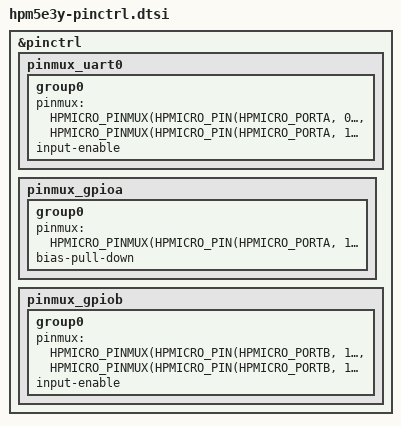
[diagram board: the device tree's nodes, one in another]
/*
 * Copyright (c) 2026 HPMicro
 * SPDX-License-Identifier: Apache-2.0
 */

#include "dt-bindings/pinctrl/hpmicro-pinctrl-common.h"

&pinctrl {
	pinmux_uart0: pinmux_uart0 {
		group0 {
			pinmux = <HPMICRO_PINMUX(HPMICRO_PIN(HPMICRO_PORTA, 0), IOC_TYPE_IOC, 0, 2)>,
				 <HPMICRO_PINMUX(HPMICRO_PIN(HPMICRO_PORTA, 1), IOC_TYPE_IOC, 0, 2)>;
			input-enable;
		};
	};

	pinmux_gpioa: pinmux_gpioa {
		group0 {
			pinmux = <HPMICRO_PINMUX(HPMICRO_PIN(HPMICRO_PORTA, 10), IOC_TYPE_IOC, 0, 0)>;
			bias-pull-down;
		};
	};

	pinmux_gpiob: pinmux_gpiob {
		group0 {
			pinmux = <HPMICRO_PINMUX(HPMICRO_PIN(HPMICRO_PORTB, 14), IOC_TYPE_IOC, 0, 0)>,
				 <HPMICRO_PINMUX(HPMICRO_PIN(HPMICRO_PORTB, 15), IOC_TYPE_IOC, 0, 0)>;
			input-enable;
		};
	};
};
